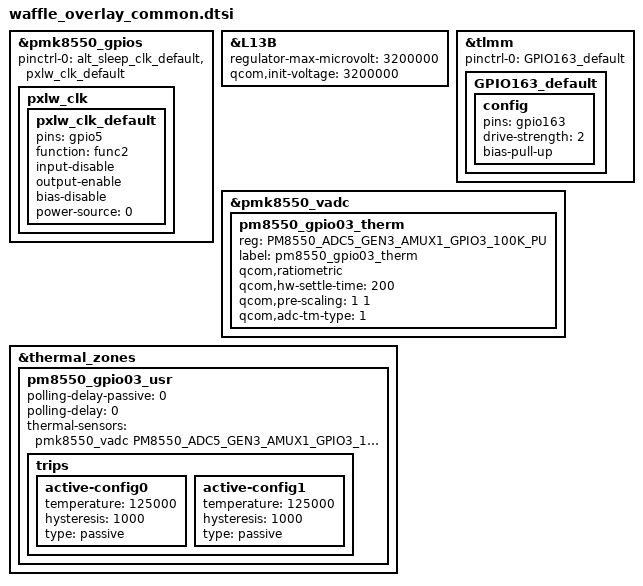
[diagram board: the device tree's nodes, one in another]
//#if defined(PXLW_IRIS)
&pmk8550_gpios {
	/delete-property/ pinctrl-0;
	pinctrl-0 = <&alt_sleep_clk_default &pxlw_clk_default>;
	pinctrl-names = "default";

	pxlw_clk {
		pxlw_clk_default: pxlw_clk_default {
			pins = "gpio5";
			function = "func2";
			input-disable;
			output-enable;
			bias-disable;
			power-source = <0>;
		};
	};
};
//#endif /* PXLW_IRIS */

//#ifdef OPLUS_FEATURE_DISPLAY
&L13B {
	regulator-max-microvolt = <3200000>;
	qcom,init-voltage = <3200000>;
};
&tlmm {
	pinctrl-names = "default";
	pinctrl-0 = <&GPIO163_default>;

	GPIO163_default: GPIO163_default {
		config {
			pins = "gpio163";
			drive-strength = <2>;
			bias-pull-up;
		};
	};
};
//#endif /* OPLUS_FEATURE_DISPLAY */

&pmk8550_vadc {
	pm8550_gpio03_therm {
		reg = <PM8550_ADC5_GEN3_AMUX1_GPIO3_100K_PU>;
		label = "pm8550_gpio03_therm";
		qcom,ratiometric;
		qcom,hw-settle-time = <200>;
		qcom,pre-scaling = <1 1>;
		qcom,adc-tm-type = <1>;
	};
};

&thermal_zones {
	pm8550_gpio03_usr {
		polling-delay-passive = <0>;
		polling-delay = <0>;
		thermal-sensors = <&pmk8550_vadc PM8550_ADC5_GEN3_AMUX1_GPIO3_100K_PU>;
		trips {
			active-config0 {
				temperature = <125000>;
				hysteresis = <1000>;
				type = "passive";
			};
			active-config1 {
				temperature = <125000>;
				hysteresis = <1000>;
				type = "passive";
			};
		};
	};
};
